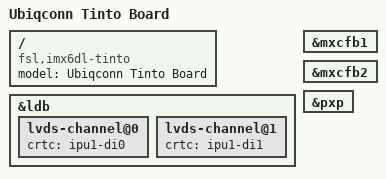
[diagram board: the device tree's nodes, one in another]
/*
 * Copyright (C) 2016 UBIQCONN TECHNOLOGY, Inc.
 *
 * This program is free software; you can redistribute it and/or modify
 * it under the terms of the GNU General Public License version 2 as
 * published by the Free Software Foundation.
 */

/dts-v1/;

#define TINTO_PVT_BOARD
#define TINIO_MP_BOARD

#include "imx6dl.dtsi"
#include "imx6qdl-tinto.dtsi"

/ {
	model = "Ubiqconn Tinto Board";
	compatible = "fsl,imx6dl-tinto", "fsl,imx6dl";
};

&ldb {
	lvds-channel@0 {
		crtc = "ipu1-di0";
	};

	lvds-channel@1 {
		crtc = "ipu1-di1";
	};
};

&mxcfb1 {
	status = "okay";
};

&mxcfb2 {
	status = "okay";
};

&pxp {
	status = "okay";
};

